# MIMXRT1052 register map
Vendor: nxp.com; File version: 1.0
CPU: CM7 r0p1, little endian, MPU, FPU, VTOR, 4 interrupt priority bits
Registers are 32-bit, read-write, reset 0x0 unless marked. A register's access mark holds for its fields unless they carry their own. Offsets are from the block's base; [hi:lo] are bit positions; lines under a group give offsets from that group; {n}, {i} and the like mark numbered series; 'fields as' and 'values as' point back to an identical list.

## AIPSTZ1 — AIPSTZ Control Registers
Base 0x4007C000; register names take the prefix AIPSTZ1_
Same registers: AIPSTZ2 0x4017C000 (register names take the prefix AIPSTZ2_), AIPSTZ3 0x4027C000 (register names take the prefix AIPSTZ3_), AIPSTZ4 0x4037C000 (register names take the prefix AIPSTZ4_)
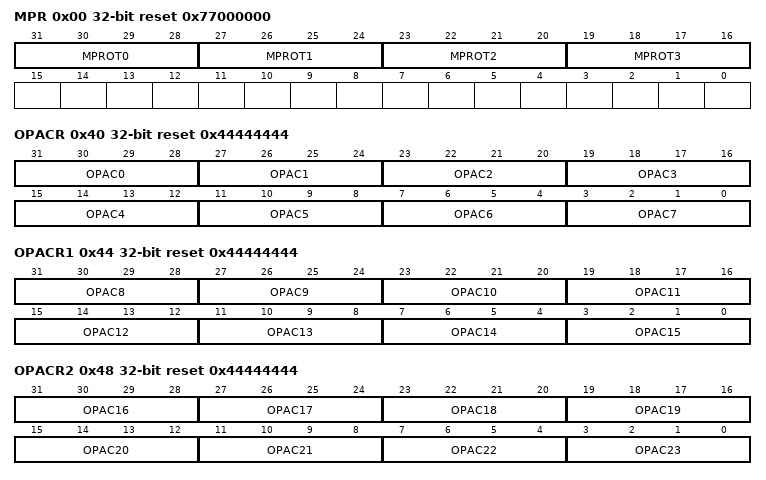
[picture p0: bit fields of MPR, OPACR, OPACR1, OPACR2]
0x00 MPR reset 0x77000000 — Master Priviledge Registers
  [all] fields
    0bxxx0=MPL0 (Accesses from this master are forced to user-mode (ips_supervisor_access is forced to zero) regardless of the hprot[1] access attribute.); 0bxxx1=MPL1 (Accesses from this master are not forced to user-mode. The hprot[1] access attribute is used directly to determine ips_supervisor_access.)
  [31:28] MPROT0 — Master 0 Priviledge, Buffer, Read, Write Control
  [27:24] MPROT1 — Master 1 Priviledge, Buffer, Read, Write Control
  [23:20] MPROT2 — Master 2 Priviledge, Buffer, Read, Write Control
  [19:16] MPROT3 — Master 3 Priviledge, Buffer, Read, Write Control.
0x40 OPACR reset 0x44444444 — Off-Platform Peripheral Access Control Registers
  [all] fields
    0bxxx0=TP0 (Accesses from an untrusted master are allowed.); 0bxxx1=TP1 (Accesses from an untrusted master are not allowed. If an access is attempted by an untrusted master, the access is terminated with an error response and no peripheral access is initiated on the IPS bus.)
  [31-4n:28-4n] OPAC{n} (n=0..7) — Off-platform Peripheral Access Control {n}
0x44 OPACR1 reset 0x44444444 — Off-Platform Peripheral Access Control Registers
  [all] fields
    values as the fields of OPACR
  [63-4n:60-4n] OPAC{n} (n=8..15) — Off-platform Peripheral Access Control {n}
0x48 OPACR2 reset 0x44444444 — Off-Platform Peripheral Access Control Registers
  [all] fields
    values as the fields of OPACR
  [95-4n:92-4n] OPAC{n} (n=16..23) — Off-platform Peripheral Access Control {n}
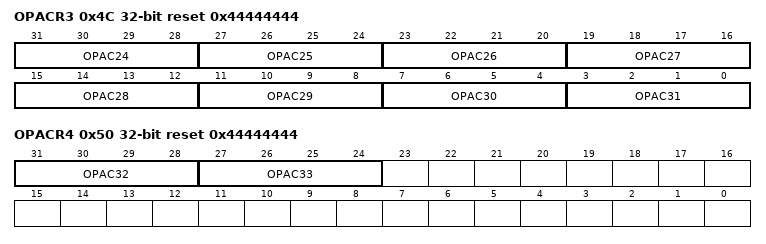
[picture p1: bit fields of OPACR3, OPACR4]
0x4C OPACR3 reset 0x44444444 — Off-Platform Peripheral Access Control Registers
  [all] fields
    values as the fields of OPACR
  [127-4n:124-4n] OPAC{n} (n=24..31) — Off-platform Peripheral Access Control {n}
0x50 OPACR4 reset 0x44444444 — Off-Platform Peripheral Access Control Registers
  [31:28] OPAC32 — Off-platform Peripheral Access Control 32
    values as the fields of OPACR
  [27:24] OPAC33 — Off-platform Peripheral Access Control 33
    values as the fields of OPACR

## PIT
Base 0x40084000
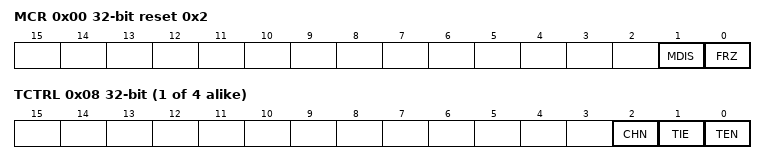
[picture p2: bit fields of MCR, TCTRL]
0x00 MCR reset 0x2 — PIT Module Control Register
  [1] MDIS — Module Disable for PIT
    0=Clock for standard PIT timers is enabled; 1=Clock for standard PIT timers is disabled
  [0] FRZ — Freeze
    0=Timers continue to run in Debug mode; 1=Timers are stopped in Debug mode
0xE0 LTMR64H ro — PIT Upper Lifetime Timer Register
  [31:0] LTH — Life Timer value
0xE4 LTMR64L ro — PIT Lower Lifetime Timer Register
  [31:0] LTL — Life Timer value
{0x100+0x10*i} TIMER[{i}] (i=0..3) group
  0x00 LDVAL — Timer Load Value Register
    [31:0] TSV — Timer Start Value
  0x04 CVAL ro — Current Timer Value Register
    [31:0] TVL — Current Timer Value
  0x08 TCTRL — Timer Control Register
    [2] CHN — Chain Mode
      0=Timer is not chained; 1=Timer is chained to a previous timer. For example, for channel 2, if this field is set, Timer 2 is chained to Timer 1.
    [1] TIE — Timer Interrupt Enable
      0=Interrupt requests from Timer n are disabled; 1=Interrupt is requested whenever TIF is set
    [0] TEN — Timer Enable
      0=Timer n is disabled; 1=Timer n is enabled
  0x0C TFLG — Timer Flag Register
    [0] TIF write-1-clears — Timer Interrupt Flag
      0=Timeout has not yet occurred; 1=Timeout has occurred

## CMP1 — High-Speed Comparator (CMP), Voltage Reference (VREF) Digital-to-Analog Converter (DAC), and Analog Mux (ANMUX)
Base 0x40094000; register names take the prefix CMP1_
Same registers: CMP2 0x40094008 (register names take the prefix CMP2_), CMP3 0x40094010 (register names take the prefix CMP3_), CMP4 0x40094018 (register names take the prefix CMP4_)
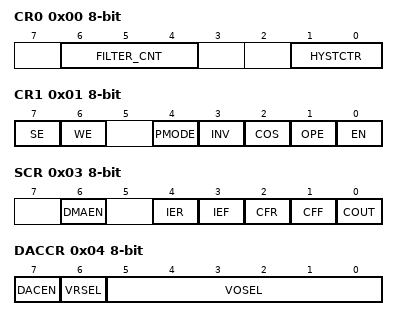
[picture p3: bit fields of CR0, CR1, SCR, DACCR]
0x00 CR0 8-bit — CMP Control Register 0
  [6:4] FILTER_CNT — Filter Sample Count
    0=Filter is disabled. If SE = 1, then COUT is a logic 0. This is not a legal state, and is not recommended. If SE = 0, COUT = COUTA.; 1=One sample must agree. The comparator output is simply sampled.; {v}={v} consecutive samples must agree (v=2..7)
  [1:0] HYSTCTR — Comparator hard block hysteresis control
    {v}=Level {v} (v=0..3)
0x01 CR1 8-bit — CMP Control Register 1
  [7] SE — Sample Enable
    0=Sampling mode is not selected; 1=Sampling mode is selected
  [6] WE — Windowing Enable
    0=Windowing mode is not selected; 1=Windowing mode is selected
  [4] PMODE — Power Mode Select
    0=Low-Speed (LS) Comparison mode selected. In this mode, CMP has slower output propagation delay and lower current consumption.; 1=High-Speed (HS) Comparison mode selected. In this mode, CMP has faster output propagation delay and higher current consumption.
  [3] INV — Comparator INVERT
    0=Does not invert the comparator output; 1=Inverts the comparator output
  [2] COS — Comparator Output Select
    0=Set the filtered comparator output (CMPO) to equal COUT; 1=Set the unfiltered comparator output (CMPO) to equal COUTA
  [1] OPE — Comparator Output Pin Enable
    0=CMPO is not available on the associated CMPO output pin. If the comparator does not own the pin, this field has no effect.; 1=CMPO is available on the associated CMPO output pin. The comparator output (CMPO) is driven out on the associated CMPO output pin if the comparator owns the pin. If the comparator does not own the field, this bit has no effect.
  [0] EN — Comparator Module Enable
    0=Analog Comparator is disabled; 1=Analog Comparator is enabled
0x02 FPR 8-bit — CMP Filter Period Register
  [7:0] FILT_PER — Filter Sample Period
0x03 SCR 8-bit — CMP Status and Control Register
  [6] DMAEN — DMA Enable Control
    0=DMA is disabled; 1=DMA is enabled
  [4] IER — Comparator Interrupt Enable Rising
    0=Interrupt is disabled; 1=Interrupt is enabled
  [3] IEF — Comparator Interrupt Enable Falling
    0=Interrupt is disabled; 1=Interrupt is enabled
  [2] CFR write-1-clears — Analog Comparator Flag Rising
    0=Rising-edge on COUT has not been detected; 1=Rising-edge on COUT has occurred
  [1] CFF write-1-clears — Analog Comparator Flag Falling
    0=Falling-edge on COUT has not been detected; 1=Falling-edge on COUT has occurred
  [0] COUT ro — Analog Comparator Output
0x04 DACCR 8-bit — DAC Control Register
  [7] DACEN — DAC Enable
    0=DAC is disabled; 1=DAC is enabled
  [6] VRSEL — Supply Voltage Reference Source Select
    0=Vin1 is selected as resistor ladder network supply reference; 1=Vin2 is selected as resistor ladder network supply reference
  [5:0] VOSEL — DAC Output Voltage Select
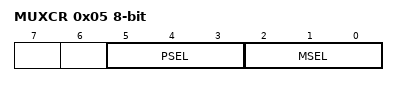
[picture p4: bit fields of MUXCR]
0x05 MUXCR 8-bit — MUX Control Register
  [5:3] PSEL — Plus Input Mux Control
    {v}=IN{v} (v=0..7)
  [2:0] MSEL — Minus Input Mux Control
    {v}=IN{v} (v=0..7)

## Notices in the file
Copyright 2016-2021 NXP
All rights reserved.
SPDX-License-Identifier: BSD-3-Clause
